AUTOSAR XML (schema 00047)
package /ServiceSwComponent_LIN
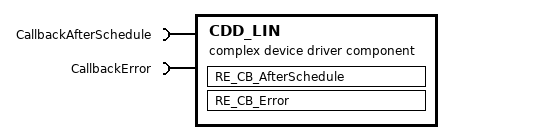
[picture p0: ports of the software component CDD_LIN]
  complex device driver sw component type CDD_LIN
    require port CallbackAfterSchedule: client-com-spec=lin_after_schedule, required-interface=CallbackAfterSchedule
    require port CallbackError: client-com-spec=lin_cbk_err, required-interface=CallbackError
    behavior SwcIB_LIN: handle-termination-and-restart=NO-SUPPORT
      runnable RE_CB_AfterSchedule: can-be-invoked-concurrently=true
        sync call SSCP_RE_CB_AfterSchedule_CallbackAfterSchedule_lin_after_schedule: operation=CallbackAfterSchedule.lin_after_schedule
      runnable RE_CB_Error: can-be-invoked-concurrently=true
        sync call SSCP_RE_CB_Error_CallbackError_lin_cbk_err: operation=CallbackError.lin_cbk_err
package /ServiceSwComponent_LIN/ClientServerInterface
  client server interface CallbackAfterSchedule: is-service=true
    operation lin_after_schedule
      4 x arg, all with type=uint8, direction=IN:
        channelId
        schId
        schEntryNum
        frameId
  client server interface CallbackError: is-service=true
    operation lin_cbk_err
      4 x arg, all with type=uint8, direction=IN:
        channelId
        errcode
        schEntryNum
        frameId
